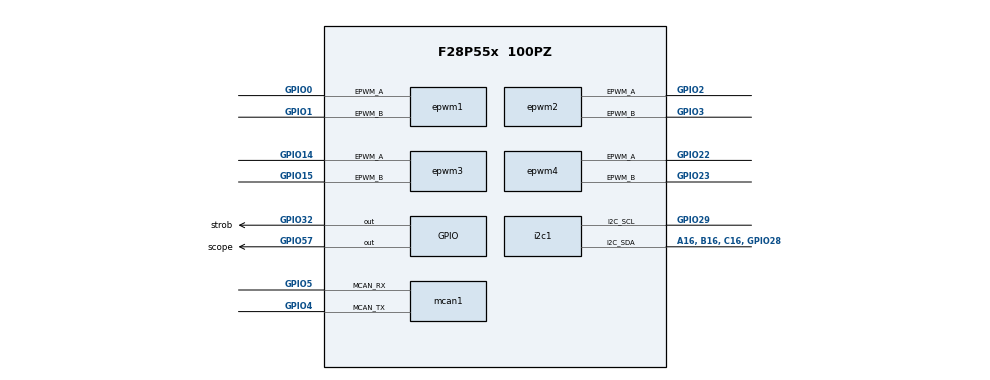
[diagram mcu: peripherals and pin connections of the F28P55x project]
/**
 *
 * @cliArgs --device "F28P55x" --part "F28P55x_100PZ" --package "100PZ" --context "system" --product "C2000WARE@26.01.00.00"
 * @versions {"tool":"1.28.0+4696"}
 */

/**
 * Import the modules used in this configuration.
 */
const adc            = scripting.addModule("/driverlib/adc.js", {}, false);
const adc1           = adc.addInstance();
const adc2           = adc.addInstance();
const adc3           = adc.addInstance();
const analog         = scripting.addModule("/driverlib/analog.js", {}, false);
const analog1        = analog.addInstance();
const asysctl        = scripting.addModule("/driverlib/asysctl.js");
const cla            = scripting.addModule("/driverlib/cla.js", {}, false);
const cla1           = cla.addInstance();
const clb            = scripting.addModule("/driverlib/clb.js", {}, false);
const clb1           = clb.addInstance();
const cmpss          = scripting.addModule("/driverlib/cmpss.js", {}, false);
const cmpss1         = cmpss.addInstance();
const cmpss2         = cmpss.addInstance();
const cmpss3         = cmpss.addInstance();
const cmpss4         = cmpss.addInstance();
const dac            = scripting.addModule("/driverlib/dac.js", {}, false);
const dac1           = dac.addInstance();
const device_support = scripting.addModule("/driverlib/device_support.js");
const ecap           = scripting.addModule("/driverlib/ecap.js", {}, false);
const ecap1          = ecap.addInstance();
const epwm           = scripting.addModule("/driverlib/epwm.js");
const epwm1          = epwm.addInstance();
const epwm2          = epwm.addInstance();
const epwm3          = epwm.addInstance();
const epwm4          = epwm.addInstance();
const epwm5          = epwm.addInstance();
const epwm6          = epwm.addInstance();
const epwm7          = epwm.addInstance();
const epwm8          = epwm.addInstance();
const gpio           = scripting.addModule("/driverlib/gpio.js", {}, false);
const gpio1          = gpio.addInstance();
const gpio2          = gpio.addInstance();
const i2c            = scripting.addModule("/driverlib/i2c.js", {}, false);
const i2c1           = i2c.addInstance();
const mcan           = scripting.addModule("/driverlib/mcan.js", {}, false);
const mcan1          = mcan.addInstance();
const memcfg         = scripting.addModule("/driverlib/memcfg.js");
const spi            = scripting.addModule("/driverlib/spi.js", {}, false);
const spi1           = spi.addInstance();
const TILE           = scripting.addModule("/utilities/clb_tool/clb_syscfg/source/TILE", {}, false);
const TILE1          = TILE.addInstance();

/**
 * Write custom configuration values to the imported modules.
 */
adc1.$name                          = "myADCA";
adc1.adcClockPrescaler              = "ADC_CLK_DIV_2_0";
adc1.interruptPulseMode             = "ADC_PULSE_END_OF_CONV";
adc1.socHighPriorityMode            = "ADC_PRI_ALL_HIPRI";
adc1.soc0Trigger                    = "ADC_TRIGGER_EPWM1_SOCA";
adc1.soc1Name                       = "SOC1_Vin";
adc1.soc1Channel                    = "ADC_CH_ADCIN4";
adc1.soc1Trigger                    = "ADC_TRIGGER_EPWM1_SOCA";
adc1.soc2Name                       = "SOC2_Idc";
adc1.soc2Channel                    = "ADC_CH_ADCIN12";
adc1.soc2Trigger                    = "ADC_TRIGGER_EPWM1_SOCA";
adc1.enableInterrupt1ContinuousMode = true;
adc1.ppb1HighTripLimit              = 2000;
adc1.ppb1LowTripLimit               = -2000;
adc1.ppb2SOCNumber                  = "ADC_SOC_NUMBER1";
adc1.ppb2HighTripLimit              = 4000;
adc1.ppb2ReferenceOffset            = 2048;
adc1.ppb3SOCNumber                  = "ADC_SOC_NUMBER2";
adc1.ppb3ReferenceOffset            = 2048;
adc1.enableTDMA                     = false;
adc1.soc0Name                       = "SOC0_U220";
adc1.soc0SampleWindow               = 150;
adc1.ppb1ReferenceOffset            = 2048;
adc1.soc1SampleWindow               = 150;
adc1.soc2SampleWindow               = 150;
adc1.enabledSOCs                    = ["ADC_SOC_NUMBER0","ADC_SOC_NUMBER1","ADC_SOC_NUMBER2","ADC_SOC_NUMBER3"];
adc1.enabledPPBs                    = ["ADC_PPB_NUMBER1","ADC_PPB_NUMBER2","ADC_PPB_NUMBER3","ADC_PPB_NUMBER4"];
adc1.soc3Name                       = "SOC3_uSec";
adc1.soc3Channel                    = "ADC_CH_ADCIN1";
adc1.soc3Trigger                    = "ADC_TRIGGER_EPWM1_SOCA";
adc1.soc3SampleWindow               = 150;
adc1.ppb4SOCNumber                  = "ADC_SOC_NUMBER3";
adc1.ppb4ReferenceOffset            = 2048;
adc1.enabledInts                    = ["ADC_INT_NUMBER1","ADC_INT_NUMBER2"];
adc1.enableInterrupt2               = true;
adc1.interrupt2SOCSource            = "ADC_INT_TRIGGER_EOC3";
adc1.enableInterrupt2ContinuousMode = true;

adc2.$name                          = "myADCB";
adc2.adcBase                        = "ADCB_BASE";
adc2.adcClockPrescaler              = "ADC_CLK_DIV_2_0";
adc2.interruptPulseMode             = "ADC_PULSE_END_OF_CONV";
adc2.socHighPriorityMode            = "ADC_PRI_ALL_HIPRI";
adc2.enabledSOCs                    = ["ADC_SOC_NUMBER0","ADC_SOC_NUMBER1"];
adc2.enabledInts                    = ["ADC_INT_NUMBER1"];
adc2.enabledPPBs                    = ["ADC_PPB_NUMBER1","ADC_PPB_NUMBER2"];
adc2.soc0Name                       = "SOC0_Ia";
adc2.soc1Name                       = "SOC1_Ib";
adc2.enableInterrupt1               = true;
adc2.interrupt1SOCSource            = "ADC_INT_TRIGGER_EOC1";
adc2.enableInterrupt1ContinuousMode = true;
adc2.ppb1ReferenceOffset            = 2048;
adc2.ppb2SOCNumber                  = "ADC_SOC_NUMBER1";
adc2.ppb2ReferenceOffset            = 2048;
adc2.soc0Trigger                    = "ADC_TRIGGER_EPWM1_SOCA";
adc2.soc1Trigger                    = "ADC_TRIGGER_EPWM1_SOCA";
adc2.soc0Channel                    = "ADC_CH_ADCIN1";
adc2.soc1Channel                    = "ADC_CH_ADCIN4";
adc2.registerInterrupts             = ["1"];
adc2.soc0SampleWindow               = 150;
adc2.soc1SampleWindow               = 150;
adc2.adcInt1.enableInterrupt        = true;

adc3.$name                          = "myADCC";
adc3.adcBase                        = "ADCC_BASE";
adc3.adcClockPrescaler              = "ADC_CLK_DIV_2_0";
adc3.interruptPulseMode             = "ADC_PULSE_END_OF_CONV";
adc3.enabledSOCs                    = ["ADC_SOC_NUMBER0"];
adc3.soc0Channel                    = "ADC_CH_ADCIN12";
adc3.soc0SampleWindow               = 512;
adc3.enableInterrupt1ContinuousMode = true;
adc3.enableTDMA                     = false;
adc3.socHighPriorityMode            = "ADC_PRI_ALL_HIPRI";
adc3.soc0Trigger                    = "ADC_TRIGGER_EPWM1_SOCA";

asysctl.enableTemperatureSensor = true;
asysctl.analogReference         = "INTERNAL";
asysctl.externalDACLEnable      = true;
asysctl.analogReferenceVoltage  = "1P65";

cla1.$name             = "myCLA0";
cla1.enable_CLA_TASK_2 = false;
cla1.enable_CLA_TASK_3 = false;
cla1.enable_CLA_TASK_4 = false;
cla1.enable_CLA_TASK_5 = false;
cla1.enable_CLA_TASK_6 = false;
cla1.enable_CLA_TASK_8 = false;
cla1.enable_CLA_TASK_7 = false;
cla1.cpuint_CLA_TASK_1 = false;
cla1.cpuint_CLA_TASK_2 = false;
cla1.cpuint_CLA_TASK_3 = false;
cla1.cpuint_CLA_TASK_4 = false;
cla1.cpuint_CLA_TASK_5 = false;
cla1.cpuint_CLA_TASK_6 = false;
cla1.cpuint_CLA_TASK_7 = false;
cla1.cpuint_CLA_TASK_8 = false;

clb1.$name               = "myCLB0";
clb1.enableCLB           = true;
clb1.inputTypeCLB_IN0    = "GLOBAL";
clb1.inputTypeCLB_IN1    = "GLOBAL";
clb1.globalConfigCLB_IN1 = "CLB_GLOBAL_IN_MUX_EPWM1B";
clb1.synchronizeCLB_IN0  = true;
clb1.synchronizeCLB_IN1  = true;
clb1.inputTypeCLB_IN2    = "GLOBAL";
clb1.synchronizeCLB_IN2  = true;
clb1.globalConfigCLB_IN2 = "CLB_GLOBAL_IN_MUX_EPWM2A";
clb1.inputTypeCLB_IN3    = "GLOBAL";
clb1.synchronizeCLB_IN3  = true;
clb1.globalConfigCLB_IN3 = "CLB_GLOBAL_IN_MUX_EPWM2B";
clb1.inputsUsed          = ["CLB_IN0","CLB_IN1","CLB_IN2","CLB_IN3","CLB_IN4","CLB_IN5","CLB_IN6","CLB_IN7"];
clb1.inputTypeCLB_IN4    = "GLOBAL";
clb1.synchronizeCLB_IN4  = true;
clb1.globalConfigCLB_IN4 = "CLB_GLOBAL_IN_MUX_EPWM3A";
clb1.inputTypeCLB_IN5    = "GLOBAL";
clb1.synchronizeCLB_IN5  = true;
clb1.globalConfigCLB_IN5 = "CLB_GLOBAL_IN_MUX_EPWM3B";
clb1.inputTypeCLB_IN6    = "GLOBAL";
clb1.synchronizeCLB_IN6  = true;
clb1.globalConfigCLB_IN6 = "CLB_GLOBAL_IN_MUX_EPWM4A";
clb1.inputTypeCLB_IN7    = "GLOBAL";
clb1.globalConfigCLB_IN7 = "CLB_GLOBAL_IN_MUX_EPWM4B";
clb1.synchronizeCLB_IN7  = true;
clb1.attachTile          = true;
clb1.initTile            = true;

const divider4       = system.clockTree["MCANACLKDIV"];
divider4.divideValue = 1;

const divider8       = system.clockTree["PLL_REFDIV"];
divider8.divideValue = 2;

const mux3       = system.clockTree["OSCCLKSRCSEL"];
mux3.inputSelect = "X1_XTAL";

cmpss1.$name               = "myCMPSS3";
cmpss1.cmpssBase           = "CMPSS3_BASE";
cmpss1.enableModule        = true;
cmpss1.dacValHigh          = 2048;
cmpss1.asysCMPHPMXSELValue = "2";
cmpss1.hysteresisVal       = "4";
cmpss1.samplePrescaleHigh  = 187;
cmpss1.sampleWindowHigh    = 32;
cmpss1.thresholdHigh       = 32;
cmpss1.initFilterHigh      = true;
cmpss1.highCTRIP           = "CMPSS_TRIP_FILTER";

cmpss2.$name               = "myCMPSS1";
cmpss2.enableModule        = true;
cmpss2.dacValHigh          = 3500;
cmpss2.dacValLow           = 400;
cmpss2.asysCMPLPMXSELValue = "4";

cmpss3.$name               = "myCMPSS2";
cmpss3.cmpssBase           = "CMPSS2_BASE";
cmpss3.asysCMPHPMXSELValue = "3";
cmpss3.dacValHigh          = 3800;
cmpss3.dacValLow           = 400;
cmpss3.asysCMPLPMXSELValue = "3";
cmpss3.enableModule        = true;

cmpss4.$name        = "myCMPSS4";
cmpss4.cmpssBase    = "CMPSS4_BASE";
cmpss4.enableModule = true;

dac1.$name        = "myDAC1";
dac1.gainMode     = "DAC_GAIN_TWO";
dac1.shadowValue  = 400;
dac1.enableOutput = true;
scripting.suppress("The pin A0, B15, C15, DACA_OUT is also selected by the ADC module\\. The DAC output will be driving the ADC pin input\\. This is an acceptable use-case\\.", dac1, "dacDevicePinName");
scripting.suppress("The pin A0, B15, C15, DACA_OUT is also selected by the CMPSS module\\. The DAC output will be driving the CMPSS pin input\\. This is an acceptable use-case\\.", dac1, "dacDevicePinName");

analog1.$name            = "myANALOGPinMux0";
adc1.analog              = analog1;
adc2.analog              = analog1;
adc3.analog              = analog1;
dac1.analog              = analog1;
cmpss1.analog            = analog1;
cmpss2.analog            = analog1;
cmpss3.analog            = analog1;
cmpss4.analog            = analog1;
analog1.useCase          = "CUSTOM";
analog1.useInterfacePins = ["A0, B15, C15, DACA_OUT","A1, B7, D11, CMP1_DACL","A10, B1, C10, GPIO230","A12, C5","A2, B6, C9, PGA1_INP, GPIO224","A4, B8","B2, C6, E12, GPIO226","B4, C8, GPIO236"];

ecap1.$name                   = "U220_zero_ECAP";
ecap1.ecapInput               = "ECAP_INPUT_CMPSS3_CTRIP_HIGH";
ecap1.registerInterrupts      = true;
ecap1.enableInterrupt         = true;
ecap1.interruptSourceCapture  = ["ECAP_ISR_SOURCE_CAPTURE_EVENT_1"];
ecap1.ecapInt.enableInterrupt = true;

epwm.generateInitFunctions = true;
epwm.commentOutDefaultCode = true;
epwm.enableAllCode         = true;

epwm1.$name                                                      = "myEPWM1";
epwm1.useCase                                                    = "CUSTOM";
epwm1.epwmTimebase_emulationMode                                 = "EPWM_EMULATION_FREE_RUN";
epwm1.epwmTimebase_syncInPulseSource                             = "EPWM_SYNC_IN_PULSE_SRC_DISABLE";
epwm1.epwmTimebase_syncOutPulseMode                              = ["EPWM_SYNC_OUT_PULSE_ON_CNTR_ZERO"];
epwm1.useInterfacePins                                           = ["EPWM#_A","EPWM#_B"];
epwm1.generateCodeTemplate                                       = true;
epwm1.codeTemplateName                                           = "ePWM1_Template";
epwm1.epwmTimebase_period                                        = 30000;
epwm1.epwmTimebase_periodGld                                     = true;
epwm1.epwmCounterCompare_cmpA                                    = 15000;
epwm1.epwmActionQualifier_t1Source                               = "EPWM_AQ_TRIGGER_EVENT_TRIG_TZ_1";
epwm1.epwmActionQualifier_t2Source                               = "EPWM_AQ_TRIGGER_EVENT_TRIG_TZ_1";
epwm1.epwmActionQualifier_EPWM_AQ_OUTPUT_A_ON_TIMEBASE_UP_CMPA   = "EPWM_AQ_OUTPUT_HIGH";
epwm1.epwmDeadband_enableRED                                     = true;
epwm1.epwmDeadband_delayRED                                      = 150;
epwm1.epwmDeadband_enableFED                                     = true;
epwm1.epwmDeadband_delayFED                                      = 150;
epwm1.epwmEventTrigger_EPWM_SOC_A_triggerEnable                  = true;
epwm1.epwmEventTrigger_EPWM_SOC_A_triggerSource                  = "EPWM_SOC_TBCTR_PERIOD";
epwm1.epwmEventTrigger_EPWM_SOC_A_triggerEventPrescalar          = "1";
epwm1.epwmActionQualifier_EPWM_AQ_OUTPUT_A_ON_TIMEBASE_DOWN_CMPA = "EPWM_AQ_OUTPUT_LOW";
epwm1.epwmTimebase_counterMode                                   = "EPWM_COUNTER_MODE_UP_DOWN";
epwm1.epwm.$assign                                               = "EPWM1";
epwm1.epwm.epwm_aPin.$assign                                     = "GPIO0";
epwm1.epwm.epwm_bPin.$assign                                     = "GPIO1";

epwm2.$name                                                      = "myEPWM2";
epwm2.useCase                                                    = "CUSTOM";
epwm2.epwmTimebase_emulationMode                                 = "EPWM_EMULATION_FREE_RUN";
epwm2.epwmTimebase_hsClockDiv                                    = "EPWM_HSCLOCK_DIVIDER_1";
epwm2.epwmTimebase_counterMode                                   = "EPWM_COUNTER_MODE_UP_DOWN";
epwm2.epwmTimebase_counterModeAfterSync                          = "EPWM_COUNT_MODE_UP_AFTER_SYNC";
epwm2.useInterfacePins                                           = ["EPWM#_A","EPWM#_B"];
epwm2.codeTemplateName                                           = "ePWM1_Template";
epwm2.epwmTimebase_period                                        = 30000;
epwm2.epwmTimebase_periodGld                                     = true;
epwm2.epwmCounterCompare_cmpA                                    = 15000;
epwm2.epwmActionQualifier_t1Source                               = "EPWM_AQ_TRIGGER_EVENT_TRIG_TZ_1";
epwm2.epwmActionQualifier_t2Source                               = "EPWM_AQ_TRIGGER_EVENT_TRIG_TZ_1";
epwm2.epwmActionQualifier_EPWM_AQ_OUTPUT_A_ON_TIMEBASE_UP_CMPA   = "EPWM_AQ_OUTPUT_HIGH";
epwm2.epwmActionQualifier_EPWM_AQ_OUTPUT_A_ON_TIMEBASE_DOWN_CMPA = "EPWM_AQ_OUTPUT_LOW";
epwm2.epwmDeadband_enableRED                                     = true;
epwm2.epwmDeadband_delayRED                                      = 150;
epwm2.epwmDeadband_enableFED                                     = true;
epwm2.epwmDeadband_delayFED                                      = 150;
epwm2.epwmGlobalLoad_statusTimeBase                              = "TBPRD/TBPRDHR";
epwm2.epwmGlobalLoad_statusCounterCompare                        = "(none enabled)";
epwm2.epwmGlobalLoad_statusDeadBand                              = "(none enabled)";
epwm2.epwmGlobalLoad_statusActionQualifier                       = "(none enabled)";
epwm2.epwmTimebase_periodLink                                    = "EPWM_LINK_WITH_EPWM_1";
epwm2.epwm.$assign                                               = "EPWM2";
epwm2.epwm.epwm_aPin.$assign                                     = "GPIO2";
epwm2.epwm.epwm_bPin.$assign                                     = "GPIO3";

epwm3.$name                                                      = "myEPWM3";
epwm3.epwmTimebase_period                                        = 60000;
epwm3.epwmTimebase_syncInPulseSource                             = "EPWM_SYNC_IN_PULSE_SRC_DISABLE";
epwm3.epwmActionQualifier_EPWM_AQ_OUTPUT_A_ON_TIMEBASE_UP_CMPA   = "EPWM_AQ_OUTPUT_HIGH";
epwm3.epwmActionQualifier_EPWM_AQ_OUTPUT_A_ON_TIMEBASE_DOWN_CMPA = "EPWM_AQ_OUTPUT_LOW";
epwm3.epwmDeadband_delayRED                                      = 150;
epwm3.epwmDeadband_enableFED                                     = true;
epwm3.epwmDeadband_delayFED                                      = 150;
epwm3.epwmEventTrigger_enableInterrupt                           = true;
epwm3.epwmEventTrigger_registerInterrupts                        = true;
epwm3.epwmEventTrigger_interruptSource                           = "EPWM_INT_TBCTR_PERIOD";
epwm3.epwmEventTrigger_interruptEventCount                       = "1";
epwm3.epwmEventTrigger_EPWM_SOC_A_triggerEnable                  = true;
epwm3.epwmEventTrigger_EPWM_SOC_A_triggerSource                  = "EPWM_SOC_TBCTR_PERIOD";
epwm3.epwmEventTrigger_EPWM_SOC_A_triggerEventPrescalar          = "1";
epwm3.useCase                                                    = "CUSTOM";
epwm3.useInterfacePins                                           = ["EPWM#_A","EPWM#_B"];
epwm3.epwm.$assign                                               = "EPWM3";
epwm3.epwm.epwm_aPin.$assign                                     = "GPIO14";
epwm3.epwm.epwm_bPin.$assign                                     = "GPIO15";

epwm4.$name                                                      = "myEPWM4";
epwm4.epwmTimebase_period                                        = 60000;
epwm4.epwmTimebase_syncInPulseSource                             = "EPWM_SYNC_IN_PULSE_SRC_DISABLE";
epwm4.epwmActionQualifier_EPWM_AQ_OUTPUT_A_ON_TIMEBASE_UP_CMPA   = "EPWM_AQ_OUTPUT_HIGH";
epwm4.epwmActionQualifier_EPWM_AQ_OUTPUT_A_ON_TIMEBASE_DOWN_CMPA = "EPWM_AQ_OUTPUT_LOW";
epwm4.epwmDeadband_delayRED                                      = 150;
epwm4.epwmDeadband_enableFED                                     = true;
epwm4.epwmDeadband_delayFED                                      = 150;
epwm4.epwmEventTrigger_EPWM_SOC_A_triggerEnable                  = true;
epwm4.epwmEventTrigger_EPWM_SOC_A_triggerSource                  = "EPWM_SOC_TBCTR_PERIOD";
epwm4.epwmEventTrigger_EPWM_SOC_A_triggerEventPrescalar          = "1";
epwm4.useCase                                                    = "CUSTOM";
epwm4.useInterfacePins                                           = ["EPWM#_A","EPWM#_B"];
epwm4.epwm.$assign                                               = "EPWM4";
epwm4.epwm.epwm_aPin.$assign                                     = "GPIO22";
epwm4.epwm.epwm_bPin.$assign                                     = "GPIO23";

epwm5.$name                                                      = "myEPWM5";
epwm5.epwmTimebase_period                                        = 60000;
epwm5.epwmTimebase_syncInPulseSource                             = "EPWM_SYNC_IN_PULSE_SRC_DISABLE";
epwm5.epwmActionQualifier_EPWM_AQ_OUTPUT_A_ON_TIMEBASE_UP_CMPA   = "EPWM_AQ_OUTPUT_HIGH";
epwm5.epwmActionQualifier_EPWM_AQ_OUTPUT_A_ON_TIMEBASE_DOWN_CMPA = "EPWM_AQ_OUTPUT_LOW";
epwm5.epwmDeadband_delayRED                                      = 150;
epwm5.epwmDeadband_enableFED                                     = true;
epwm5.epwmDeadband_delayFED                                      = 150;
epwm5.epwmEventTrigger_EPWM_SOC_A_triggerEnable                  = true;
epwm5.epwmEventTrigger_EPWM_SOC_A_triggerSource                  = "EPWM_SOC_TBCTR_PERIOD";
epwm5.epwmEventTrigger_EPWM_SOC_A_triggerEventPrescalar          = "1";
epwm5.epwm.$assign                                               = "EPWM5";

epwm6.$name                                = "myEPWM6";
epwm6.useCase                              = "CUSTOM";
epwm6.epwmTimebase_syncInPulseSource       = "EPWM_SYNC_IN_PULSE_SRC_DISABLE";
epwm6.epwmEventTrigger_enableInterrupt     = true;
epwm6.epwmEventTrigger_registerInterrupts  = true;
epwm6.epwmEventTrigger_interruptSource     = "EPWM_INT_TBCTR_PERIOD";
epwm6.epwmEventTrigger_interruptEventCount = "1";
epwm6.epwmTimebase_period                  = 30000;
epwm6.epwmTimebase_emulationMode           = "EPWM_EMULATION_FREE_RUN";
epwm6.epwmCounterCompare_cmpA              = 15000;
epwm6.epwmTimebase_counterMode             = "EPWM_COUNTER_MODE_UP";
epwm6.epwmInt.enableInterrupt              = true;

epwm7.$name                      = "myEPWM7";
epwm7.useCase                    = "CUSTOM";
epwm7.epwmTimebase_hsClockDiv    = "EPWM_HSCLOCK_DIVIDER_1";
epwm7.epwmTimebase_emulationMode = "EPWM_EMULATION_FREE_RUN";
epwm7.epwmTimebase_counterMode   = "EPWM_COUNTER_MODE_UP";
epwm7.epwmTimebase_period        = 65535;
epwm7.epwm.$assign               = "EPWM7";

epwm8.$name                          = "myEPWM8";
epwm8.epwmTimebase_clockDiv          = "EPWM_CLOCK_DIVIDER_64";
epwm8.epwmTimebase_period            = 65535;
epwm8.epwmTimebase_counterMode       = "EPWM_COUNTER_MODE_UP";
epwm8.epwmTimebase_syncInPulseSource = "EPWM_SYNC_IN_PULSE_SRC_DISABLE";
epwm8.useCase                        = "CUSTOM";
epwm8.epwm.$assign                   = "EPWM8";

gpio1.$name           = "scope";
gpio1.direction       = "GPIO_DIR_MODE_OUT";
gpio1.gpioPin.$assign = "GPIO57";

gpio2.$name           = "strob";
gpio2.gpioPin.$assign = "GPIO32";

i2c1.$name                  = "myI2CB";
i2c1.i2c.$assign            = "I2CB";
i2c1.i2c.i2c_sdaPin.$assign = "A16, B16, C16, GPIO28";
i2c1.i2c.i2c_sclPin.$assign = "GPIO29";

mcan1.loopbackMode             = false;
mcan1.enableInterrupt          = true;
mcan1.interruptLine            = ["MCAN_INTR_LINE_NUM_0"];
mcan1.registerInterruptLine0   = true;
mcan1.rxBufElemSize            = "0";
mcan1.rxFIFO0OpMode            = "1";
mcan1.rxFIFO1OpMode            = "1";
mcan1.lse                      = 0;
mcan1.stdFilts                 = 1;
mcan1.rrfs                     = true;
mcan1.rrfe                     = true;
mcan1.rxFIFO0ElemSize          = "0";
mcan1.interruptLine0Flag       = ["MCAN_IR_RF0N_MASK"];
mcan1.$name                    = "myMCANA";
mcan1.tdcEnable                = true;
mcan1.additionalCoreConfig     = true;
mcan1.timeoutSelect            = "MCAN_TIMEOUT_SELECT_RX_FIFO0";
mcan1.anfe                     = "2";
mcan1.anfs                     = "2";
mcan1.stdFiltsUsed             = [0];
mcan1.nomRatePrescalar         = 5;
mcan1.txpEnable                = true;
mcan1.interruptFlags           = ["MCAN_IR_BO_MASK","MCAN_IR_EP_MASK","MCAN_IR_PED_MASK","MCAN_IR_RF0N_MASK","MCAN_IR_TCF_MASK"];
mcan1.registerInterruptLine1   = true;
mcan1.interruptLine1Flag       = ["MCAN_IR_BO_MASK","MCAN_IR_EP_MASK","MCAN_IR_PED_MASK"];
mcan1.tdcConfig_tdco           = 33;
mcan1.dataRatePrescalar        = 1;
mcan1.dataTimeSeg1             = 21;
mcan1.dataTimeSeg2             = 6;
mcan1.dataSynchJumpWidth       = 5;
mcan1.nomTimeSeg1              = 17;
mcan1.nomTimeSeg2              = 5;
mcan1.nomSynchJumpWidth        = 4;
mcan1.rxFIFO0size              = 10;
mcan1.txBufNum                 = 5;
mcan1.useCalcStartingAddress   = true;
mcan1.mcan.$assign             = "MCANA";
mcan1.mcan.mcan_rxPin.$assign  = "GPIO5";
mcan1.mcan.mcan_txPin.$assign  = "GPIO4";
mcan1.mcanInt0.enableInterrupt = true;
mcan1.stdFilt0.$name           = "stdFilt1";
mcan1.stdFilt0.sfid1           = 2;
mcan1.stdFilt0.sfid2           = 2;
mcan1.stdFilt0.sfec            = "MCAN_STDFILTEC_FIFO0";
mcan1.mcanInt1.enableInterrupt = true;

memcfg.config_MEMCFG_SECT_LS1 = "CLA_prog";
memcfg.config_MEMCFG_SECT_LS2 = "CLA_data";
memcfg.config_MEMCFG_SECT_LS7 = "CLA_data";

spi1.$name       = "mySPIB";
spi1.useCase     = "CUSTOM";
spi1.spi.$assign = "SPIB";

TILE1.$name              = "TILE0";
clb1.tile                = TILE1;
TILE1.BOUNDARY.$name     = "BOUNDARY0";
TILE1.LUT_0.$name        = "LUT_0";
TILE1.LUT_1.$name        = "LUT_1";
TILE1.LUT_2.$name        = "LUT_2";
TILE1.FSM_0.$name        = "FSM_0";
TILE1.FSM_1.$name        = "FSM_1";
TILE1.FSM_2.$name        = "FSM_2";
TILE1.COUNTER_0.$name    = "COUNTER_0";
TILE1.COUNTER_1.$name    = "COUNTER_1";
TILE1.COUNTER_2.$name    = "COUNTER_2";
TILE1.OUTLUT_0.$name     = "OUTLUT_0";
TILE1.OUTLUT_1.$name     = "OUTLUT_1";
TILE1.OUTLUT_2.$name     = "OUTLUT_2";
TILE1.OUTLUT_3.$name     = "OUTLUT_3";
TILE1.OUTLUT_4.$name     = "OUTLUT_4";
TILE1.OUTLUT_5.$name     = "OUTLUT_5";
TILE1.OUTLUT_6.$name     = "OUTLUT_6";
TILE1.OUTLUT_7.$name     = "OUTLUT_7";
TILE1.HLC.$name          = "HLC_0";
TILE1.HLC.program0.$name = "HLCP_0";
TILE1.HLC.program1.$name = "HLCP_1";
TILE1.HLC.program2.$name = "HLCP_2";
TILE1.HLC.program3.$name = "HLCP_3";
TILE1.AOC_0.$name        = "AOC_0";
TILE1.AOC_1.$name        = "AOC_1";
TILE1.AOC_2.$name        = "AOC_2";
TILE1.AOC_3.$name        = "AOC_3";
TILE1.AOC_4.$name        = "AOC_4";
TILE1.AOC_5.$name        = "AOC_5";
TILE1.AOC_6.$name        = "AOC_6";
TILE1.AOC_7.$name        = "AOC_7";

/**
 * Pinmux solution for unlocked pins/peripherals. This ensures that minor changes to the automatic solver in a future
 * version of the tool will not impact the pinmux you originally saw.  These lines can be completely deleted in order to
 * re-solve from scratch.
 */
analog1.analog.$suggestSolution                                     = "ANALOG";
analog1.analog["a0, b15, c15, daca_outPin"].$suggestSolution        = "A0, B15, C15, DACA_OUT";
analog1.analog["a2, b6, c9, pga1_inp, gpio224Pin"].$suggestSolution = "A2, B6, C9, PGA1_INP, GPIO224";
analog1.analog["a4, b8Pin"].$suggestSolution                        = "A4, B8";
analog1.analog["a10, b1, c10, gpio230Pin"].$suggestSolution         = "A10, B1, C10, GPIO230";
analog1.analog["a12, c5Pin"].$suggestSolution                       = "A12, C5";
analog1.analog["b2, c6, e12, gpio226Pin"].$suggestSolution          = "B2, C6, E12, GPIO226";
analog1.analog["b4, c8, gpio236Pin"].$suggestSolution               = "B4, C8, GPIO236";
analog1.analog["a1, b7, d11, cmp1_daclPin"].$suggestSolution        = "A1, B7, D11, CMP1_DACL";
epwm5.epwm.epwm_aPin.$suggestSolution                               = "GPIO37/TDO";
epwm5.epwm.epwm_bPin.$suggestSolution                               = "GPIO35/TDI";
epwm6.epwm.$suggestSolution                                         = "EPWM6";
